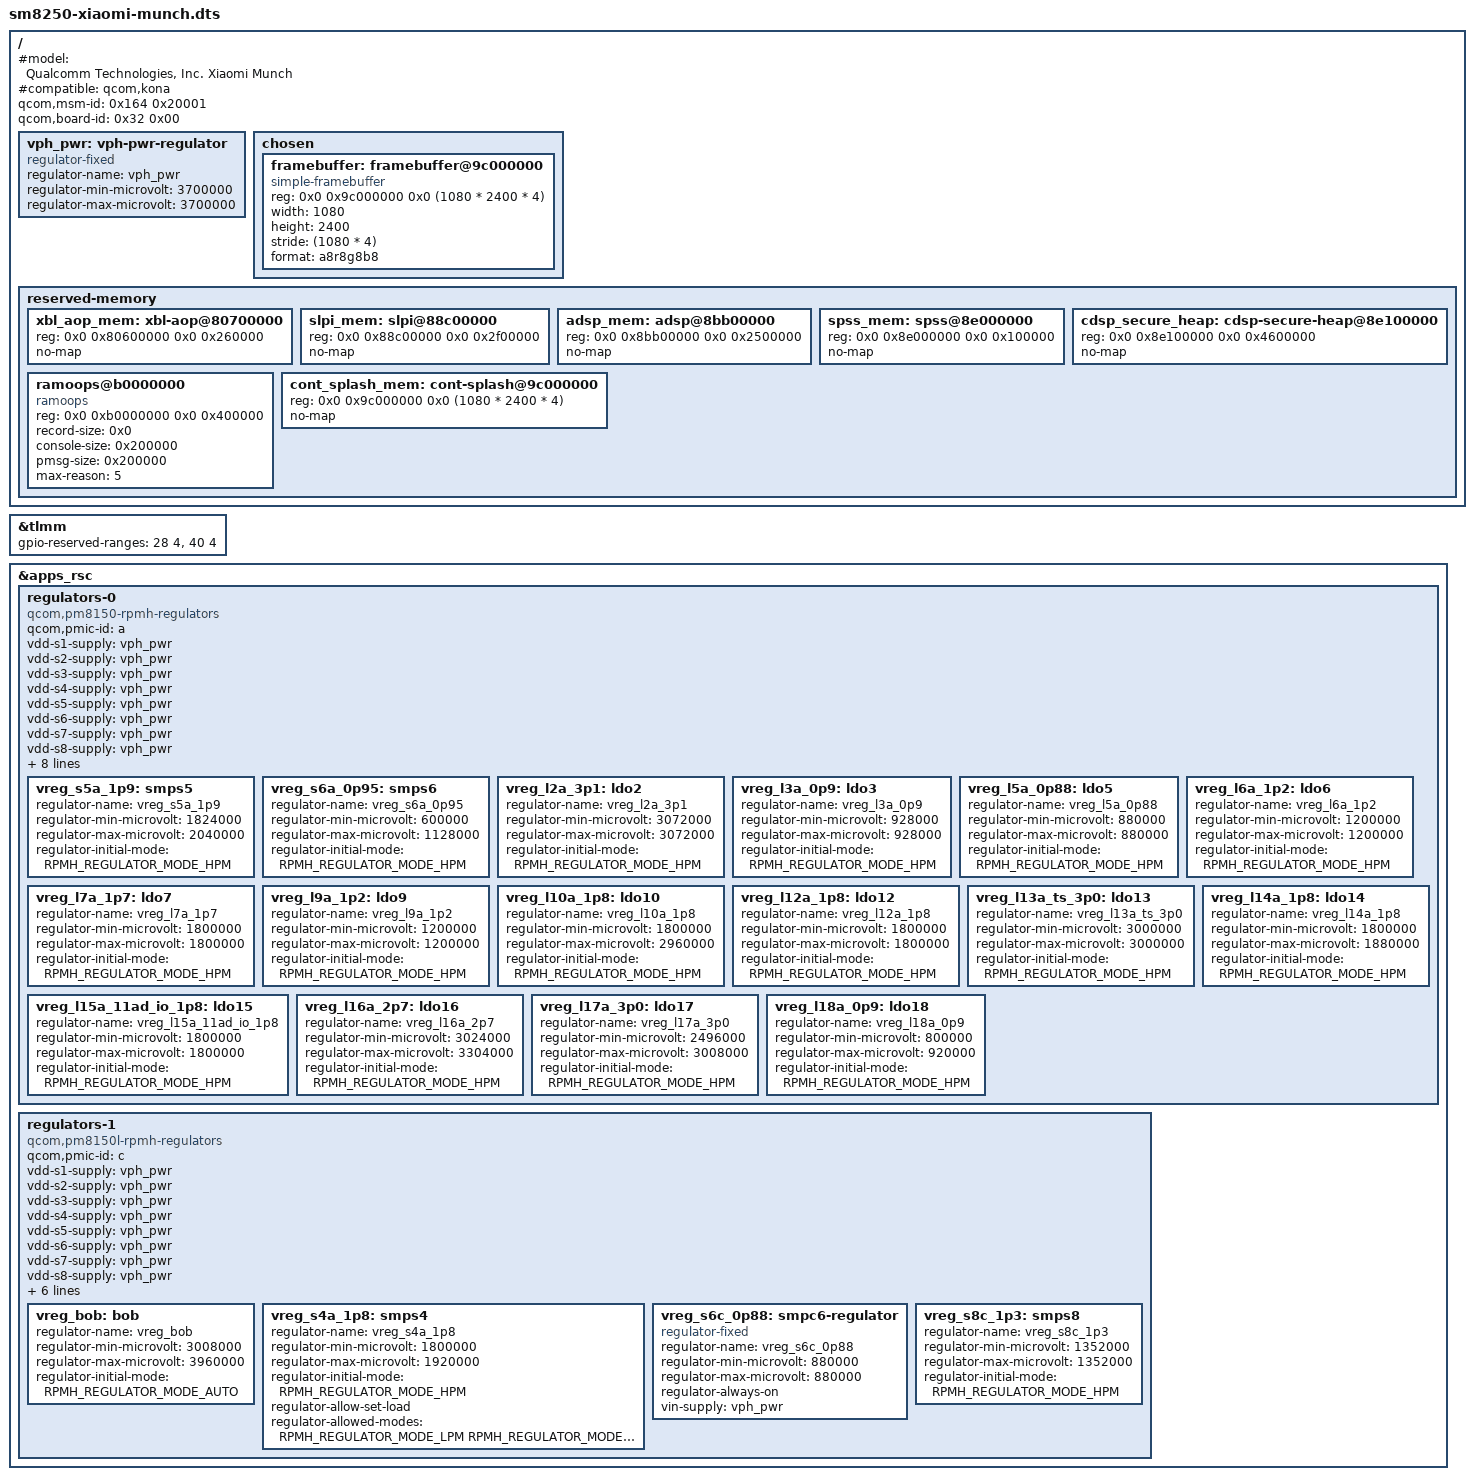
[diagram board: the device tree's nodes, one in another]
// SPDX-Identifier: GPL-2.0-only OR BSD-2-Clause
/*
 * Copyright (c) 2023 Luka msumro
 */

/dts-v1/;

#include <dt-bindings/arm/qcom,ids.h>
#include <dt-bindings/phy/phy.h>
#include <dt-bindings/regulator/qcom,rpmh-regulator.h>
#include "sm8250.dtsi"
#include "pm8150.dtsi"
#include "pm8150b.dtsi"
#include "pm8150l.dtsi"


/delete-node/ &adsp_mem;
/delete-node/ &cdsp_secure_heap;
/delete-node/ &slpi_mem;
/delete-node/ &spss_mem;
/delete-node/ &xbl_aop_mem;


/ {
    	#model = "Qualcomm Technologies, Inc. Xiaomi Munch";
    	#compatible = "qcom,kona";
    	qcom,msm-id = <0x164 0x20001>;
    	qcom,board-id = <0x32 0x00>;

	vph_pwr: vph-pwr-regulator {
		compatible = "regulator-fixed";
		regulator-name = "vph_pwr";
		regulator-min-microvolt = <3700000>;
		regulator-max-microvolt = <3700000>;
	};
	
	chosen {
		#address-cells = <2>;
		#size-cells = <2>;
		ranges;

		framebuffer: framebuffer@9c000000 {
			compatible = "simple-framebuffer";
			reg = <0x0 0x9c000000 0x0 (1080 * 2400 * 4)>;
			width = <1080>;
			height = <2400>;
			stride = <(1080 * 4)>;
			format = "a8r8g8b8";
		};
	};

    	reserved-memory {
		xbl_aop_mem: xbl-aop@80700000 {
			reg = <0x0 0x80600000 0x0 0x260000>;
			no-map;
		};

		slpi_mem: slpi@88c00000 {
			reg = <0x0 0x88c00000 0x0 0x2f00000>;
			no-map;
		};

		adsp_mem: adsp@8bb00000 {
			reg = <0x0 0x8bb00000 0x0 0x2500000>;
			no-map;
		};

		spss_mem: spss@8e000000 {
			reg = <0x0 0x8e000000 0x0 0x100000>;
			no-map;
		};

		cdsp_secure_heap: cdsp-secure-heap@8e100000 {
			reg = <0x0 0x8e100000 0x0 0x4600000>;
			no-map;
		};
		ramoops@b0000000 {
			compatible = "ramoops";
			reg = <0x0 0xb0000000 0x0 0x400000>;
			record-size = <0x0>;
			console-size = <0x200000>;
			pmsg-size = <0x200000>;
			max-reason = <5>;
		};
		cont_splash_mem: cont-splash@9c000000 {
			reg = <0x0 0x9c000000 0x0 (1080 * 2400 * 4)>;
			no-map;
		};
	};
};

&tlmm {
	gpio-reserved-ranges = <28 4>, <40 4>;
};

&apps_rsc {
	regulators-0 {
		compatible = "qcom,pm8150-rpmh-regulators";
		qcom,pmic-id = "a";


		vdd-s1-supply = <&vph_pwr>;
		vdd-s2-supply = <&vph_pwr>;
		vdd-s3-supply = <&vph_pwr>;
		vdd-s4-supply = <&vph_pwr>;
		vdd-s5-supply = <&vph_pwr>;
		vdd-s6-supply = <&vph_pwr>;
		vdd-s7-supply = <&vph_pwr>;
		vdd-s8-supply = <&vph_pwr>;
		vdd-s9-supply = <&vph_pwr>;
		vdd-s10-supply = <&vph_pwr>;
		vdd-l1-l8-l11-supply = <&vreg_s6c_0p88>;
		vdd-l2-l10-supply = <&vreg_bob>;
		vdd-l3-l4-l5-l18-supply = <&vreg_s6a_0p95>;
		vdd-l6-l9-supply = <&vreg_s8c_1p3>;
		vdd-l7-l12-l14-l15-supply = <&vreg_s5a_1p9>;
		vdd-l13-l16-l17-supply = <&vreg_bob>;


		vreg_s5a_1p9: smps5 {
			regulator-name = "vreg_s5a_1p9";
			regulator-min-microvolt = <1824000>;
			regulator-max-microvolt = <2040000>;
			regulator-initial-mode = <RPMH_REGULATOR_MODE_HPM>;
		};


		vreg_s6a_0p95: smps6 {
			regulator-name = "vreg_s6a_0p95";
			regulator-min-microvolt = <600000>;
			regulator-max-microvolt = <1128000>;
			regulator-initial-mode = <RPMH_REGULATOR_MODE_HPM>;
		};


		vreg_l2a_3p1: ldo2 {
			regulator-name = "vreg_l2a_3p1";
			regulator-min-microvolt = <3072000>;
			regulator-max-microvolt = <3072000>;
			regulator-initial-mode = <RPMH_REGULATOR_MODE_HPM>;
		};


		vreg_l3a_0p9: ldo3 {
			regulator-name = "vreg_l3a_0p9";
			regulator-min-microvolt = <928000>;
			regulator-max-microvolt = <928000>;
			regulator-initial-mode = <RPMH_REGULATOR_MODE_HPM>;
		};


		vreg_l5a_0p88: ldo5 {
			regulator-name = "vreg_l5a_0p88";
			regulator-min-microvolt = <880000>;
			regulator-max-microvolt = <880000>;
			regulator-initial-mode = <RPMH_REGULATOR_MODE_HPM>;
		};


		vreg_l6a_1p2: ldo6 {
			regulator-name = "vreg_l6a_1p2";
			regulator-min-microvolt = <1200000>;
			regulator-max-microvolt = <1200000>;
			regulator-initial-mode = <RPMH_REGULATOR_MODE_HPM>;
		};


		vreg_l7a_1p7: ldo7 {
			regulator-name = "vreg_l7a_1p7";
			regulator-min-microvolt = <1800000>;
			regulator-max-microvolt = <1800000>;
			regulator-initial-mode = <RPMH_REGULATOR_MODE_HPM>;
		};


		vreg_l9a_1p2: ldo9 {
			regulator-name = "vreg_l9a_1p2";
			regulator-min-microvolt = <1200000>;
			regulator-max-microvolt = <1200000>;
			regulator-initial-mode = <RPMH_REGULATOR_MODE_HPM>;
		};


		vreg_l10a_1p8: ldo10 {
			regulator-name = "vreg_l10a_1p8";
			regulator-min-microvolt = <1800000>;
			regulator-max-microvolt = <2960000>;
			regulator-initial-mode = <RPMH_REGULATOR_MODE_HPM>;
		};


		vreg_l12a_1p8: ldo12 {
			regulator-name = "vreg_l12a_1p8";
			regulator-min-microvolt = <1800000>;
			regulator-max-microvolt = <1800000>;
			regulator-initial-mode = <RPMH_REGULATOR_MODE_HPM>;
		};


		vreg_l13a_ts_3p0: ldo13 {
			regulator-name = "vreg_l13a_ts_3p0";
			regulator-min-microvolt = <3000000>;
			regulator-max-microvolt = <3000000>;
			regulator-initial-mode = <RPMH_REGULATOR_MODE_HPM>;
		};


		vreg_l14a_1p8: ldo14 {
			regulator-name = "vreg_l14a_1p8";
			regulator-min-microvolt = <1800000>;
			regulator-max-microvolt = <1880000>;
			regulator-initial-mode = <RPMH_REGULATOR_MODE_HPM>;
		};


		vreg_l15a_11ad_io_1p8: ldo15 {
			regulator-name = "vreg_l15a_11ad_io_1p8";
			regulator-min-microvolt = <1800000>;
			regulator-max-microvolt = <1800000>;
			regulator-initial-mode = <RPMH_REGULATOR_MODE_HPM>;
		};


		vreg_l16a_2p7: ldo16 {
			regulator-name = "vreg_l16a_2p7";
			regulator-min-microvolt = <3024000>;
			regulator-max-microvolt = <3304000>;
			regulator-initial-mode = <RPMH_REGULATOR_MODE_HPM>;
		};


		vreg_l17a_3p0: ldo17 {
			regulator-name = "vreg_l17a_3p0";
			regulator-min-microvolt = <2496000>;
			regulator-max-microvolt = <3008000>;
			regulator-initial-mode = <RPMH_REGULATOR_MODE_HPM>;
		};

		vreg_l18a_0p9: ldo18 {
			regulator-name = "vreg_l18a_0p9";
			regulator-min-microvolt = <800000>;
			regulator-max-microvolt = <920000>;
			regulator-initial-mode = <RPMH_REGULATOR_MODE_HPM>;
		};
	};

	regulators-1 {
		compatible = "qcom,pm8150l-rpmh-regulators";
		qcom,pmic-id = "c";

		vdd-s1-supply = <&vph_pwr>;
		vdd-s2-supply = <&vph_pwr>;
		vdd-s3-supply = <&vph_pwr>;
		vdd-s4-supply = <&vph_pwr>;
		vdd-s5-supply = <&vph_pwr>;
		vdd-s6-supply = <&vph_pwr>;
		vdd-s7-supply = <&vph_pwr>;
		vdd-s8-supply = <&vph_pwr>;
		vdd-l1-l8-supply = <&vreg_s4a_1p8>;
		vdd-l2-l3-supply = <&vreg_s8c_1p3>;
		vdd-l4-l5-l6-supply = <&vreg_bob>;
		vdd-l7-l11-supply = <&vreg_bob>;
		vdd-l9-l10-supply = <&vreg_bob>;
		vdd-bob-supply = <&vph_pwr>;

		vreg_bob: bob {
			regulator-name = "vreg_bob";
			regulator-min-microvolt = <3008000>;
			regulator-max-microvolt = <3960000>;
			regulator-initial-mode = <RPMH_REGULATOR_MODE_AUTO>;
		};
  vreg_s4a_1p8: smps4 {
			regulator-name = "vreg_s4a_1p8";
			regulator-min-microvolt = <1800000>;
			regulator-max-microvolt = <1920000>;
			regulator-initial-mode = <RPMH_REGULATOR_MODE_HPM>;
			regulator-allow-set-load;
			regulator-allowed-modes = <RPMH_REGULATOR_MODE_LPM
						   RPMH_REGULATOR_MODE_HPM>;
		};

		vreg_s6c_0p88: smpc6-regulator {
			compatible = "regulator-fixed";
			regulator-name = "vreg_s6c_0p88";

			regulator-min-microvolt = <880000>;
			regulator-max-microvolt = <880000>;
			regulator-always-on;
			vin-supply = <&vph_pwr>;
		};

		vreg_s8c_1p3: smps8 {
			regulator-name = "vreg_s8c_1p3";
			regulator-min-microvolt = <1352000>;
			regulator-max-microvolt = <1352000>;
			regulator-initial-mode = <RPMH_REGULATOR_MODE_HPM>;
		};

	};
};
